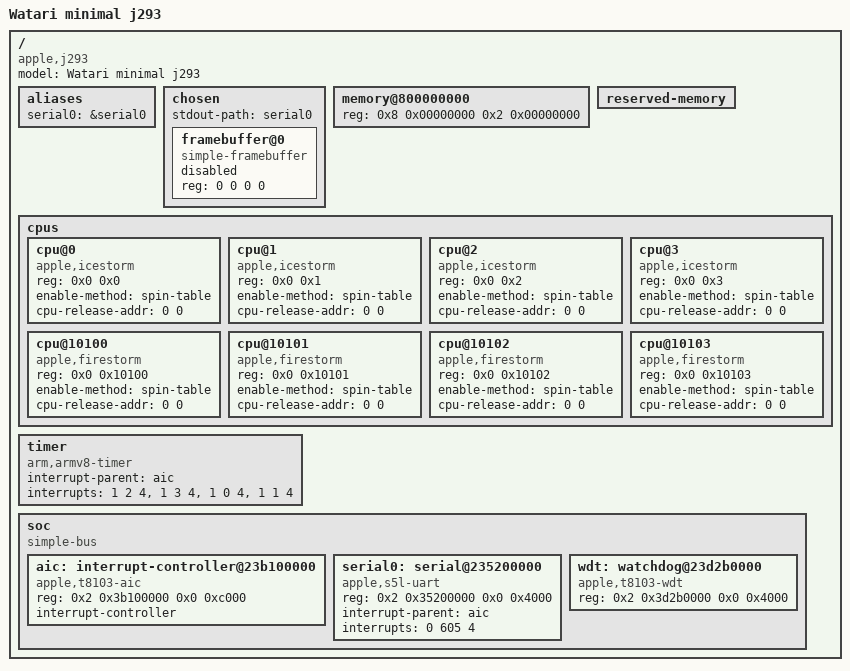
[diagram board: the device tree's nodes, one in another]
// SPDX-License-Identifier: MIT
/*
 * Watari Boot: minimal device tree for the 13" M1 MacBook Pro (j293, t8103), input of m1n1's kboot_prepare_dt()
 * (DESIGN docs/design/watari-el2-m1boot/DESIGN.md section 4.2). m1n1 fills in what is board-specific (memory
 * span, reserved regions, cpu-release-addr of the secondaries, framebuffer geometry, bootargs); every other value
 * below is a hardware fact [verified: re/m3a-ehw0-measurements.md] or a placeholder marked as such.
 *
 * Written from the Devicetree specification and our own measurements. The node shapes follow the public Linux
 * t8103.dtsi (v6.12, dual GPL-2.0 / MIT): node names, compatibles and unit addresses are cited as facts, no text
 * was copied. The root deliberately does NOT list "apple,t8103": m1n1's display fix-ups act only for known SoCs.
 * The tree carries no identifying property (no serial-number, no MAC): m1n1 adds those itself.
 */
/dts-v1/;

/ {
	compatible = "apple,j293", "watari,m1-min";
	model = "Watari minimal j293";
	#address-cells = <2>;
	#size-cells = <2>;

	aliases {
		serial0 = &serial0;
	};

	chosen {
		#address-cells = <2>;
		#size-cells = <2>;
		ranges;
		stdout-path = "serial0";

		/* m1n1 fills reg/width/height/stride/format, renames it framebuffer@<base> and drops status. */
		framebuffer@0 {
			compatible = "simple-framebuffer";
			reg = <0 0 0 0>;
			status = "disabled";
		};
	};

	/* Placeholder: m1n1 overwrites reg with the usable span (RAM base 0x800000000 on the M1). */
	memory@800000000 {
		device_type = "memory";
		reg = <0x8 0x00000000 0x2 0x00000000>;
	};

	/* m1n1 adds its own reservations as children. */
	reserved-memory {
		#address-cells = <2>;
		#size-cells = <2>;
		ranges;
	};

	cpus {
		#address-cells = <2>;
		#size-cells = <0>;

		/* reg = MPIDR_EL1 & 0xffffff, measured: E cores Aff0 0..3, P cores Aff2 1 / Aff1 1 / Aff0 0..3.
		 * cpu-release-addr is a 64-bit placeholder that m1n1 overwrites for every secondary. */
		cpu@0 {
			device_type = "cpu";
			compatible = "apple,icestorm";
			reg = <0x0 0x0>;
			enable-method = "spin-table";
			cpu-release-addr = <0 0>;
		};
		cpu@1 {
			device_type = "cpu";
			compatible = "apple,icestorm";
			reg = <0x0 0x1>;
			enable-method = "spin-table";
			cpu-release-addr = <0 0>;
		};
		cpu@2 {
			device_type = "cpu";
			compatible = "apple,icestorm";
			reg = <0x0 0x2>;
			enable-method = "spin-table";
			cpu-release-addr = <0 0>;
		};
		cpu@3 {
			device_type = "cpu";
			compatible = "apple,icestorm";
			reg = <0x0 0x3>;
			enable-method = "spin-table";
			cpu-release-addr = <0 0>;
		};
		cpu@10100 {
			device_type = "cpu";
			compatible = "apple,firestorm";
			reg = <0x0 0x10100>;
			enable-method = "spin-table";
			cpu-release-addr = <0 0>;
		};
		cpu@10101 {
			device_type = "cpu";
			compatible = "apple,firestorm";
			reg = <0x0 0x10101>;
			enable-method = "spin-table";
			cpu-release-addr = <0 0>;
		};
		cpu@10102 {
			device_type = "cpu";
			compatible = "apple,firestorm";
			reg = <0x0 0x10102>;
			enable-method = "spin-table";
			cpu-release-addr = <0 0>;
		};
		cpu@10103 {
			device_type = "cpu";
			compatible = "apple,firestorm";
			reg = <0x0 0x10103>;
			enable-method = "spin-table";
			cpu-release-addr = <0 0>;
		};
	};

	timer {
		compatible = "arm,armv8-timer";
		interrupt-parent = <&aic>;
		/* AIC_FIQ (1), numbers 2 guest phys, 3 guest virt, 0 hv phys, 1 hv virt; level high (4). Documentation
		 * only: the layer does not parse this node. */
		interrupts = <1 2 4>, <1 3 4>, <1 0 4>, <1 1 4>;
	};

	soc {
		compatible = "simple-bus";
		#address-cells = <2>;
		#size-cells = <2>;
		ranges;

		/* The ADT lists 0xc000 at 0x23b100000 plus 0x1000 at 0x23b108000 (inside the first range). */
		aic: interrupt-controller@23b100000 {
			compatible = "apple,t8103-aic", "apple,aic";
			reg = <0x2 0x3b100000 0x0 0xc000>;
			interrupt-controller;
			#interrupt-cells = <3>;
		};

		/* UART0, AIC IRQ 605 (level high), measured. */
		serial0: serial@235200000 {
			compatible = "apple,s5l-uart";
			reg = <0x2 0x35200000 0x0 0x4000>;
			interrupt-parent = <&aic>;
			interrupts = <0 605 4>;
		};

		wdt: watchdog@23d2b0000 {
			compatible = "apple,t8103-wdt", "apple,wdt";
			reg = <0x2 0x3d2b0000 0x0 0x4000>;
		};
	};
};
